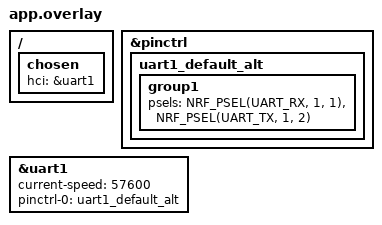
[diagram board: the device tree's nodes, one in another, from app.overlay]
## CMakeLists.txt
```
# SPDX-License-Identifier: Apache-2.0

cmake_minimum_required(VERSION 3.20.0)
find_package(Zephyr REQUIRED HINTS $ENV{ZEPHYR_BASE})
project(a2)
zephyr_library_include_directories(${ZEPHYR_BASE}/samples/bluetooth)

FILE(GLOB app_sources src/*.c)
target_sources(app PRIVATE ${app_sources})
```

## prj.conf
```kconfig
# Increased stack due to settings API usage
CONFIG_SYSTEM_WORKQUEUE_STACK_SIZE=2048

CONFIG_TEST=y
CONFIG_TEST_LOGGING_DEFAULTS=n
CONFIG_BT=y
CONFIG_LOG=y
CONFIG_BT_CENTRAL=y
CONFIG_BT_PERIPHERAL=y
CONFIG_BT_PRIVACY=y
CONFIG_BT_SMP=y
CONFIG_BT_PASSKEY_KEYPRESS=y
CONFIG_BT_SIGNING=y
CONFIG_BT_FIXED_PASSKEY=y
CONFIG_BT_ATT_PREPARE_COUNT=2
CONFIG_BT_GATT_CLIENT=y
CONFIG_BT_L2CAP_DYNAMIC_CHANNEL=y
CONFIG_BT_TINYCRYPT_ECC=y
CONFIG_BT_SHELL=y
CONFIG_BT_DEVICE_NAME="test shell"
CONFIG_BT_DEVICE_NAME_DYNAMIC=y
CONFIG_BT_L2CAP_TX_BUF_COUNT=4
CONFIG_BT_ID_MAX=2
CONFIG_BT_EATT=y
CONFIG_BT_L2CAP_ECRED=y
CONFIG_BT_GATT_DYNAMIC_DB=y
CONFIG_BT_GATT_NOTIFY_MULTIPLE=y
CONFIG_BT_HRS=y
CONFIG_BT_FILTER_ACCEPT_LIST=y
CONFIG_BT_REMOTE_INFO=y
CONFIG_BT_REMOTE_VERSION=y
CONFIG_BT_GATT_AUTO_DISCOVER_CCC=y

CONFIG_BT_SETTINGS=y
CONFIG_FLASH=y
CONFIG_FLASH_PAGE_LAYOUT=y
CONFIG_FLASH_MAP=y
CONFIG_NVS=y
CONFIG_SETTINGS=y

CONFIG_BT_EXT_ADV=y
CONFIG_BT_EXT_ADV_LEGACY_SUPPORT=y
CONFIG_BT_PER_ADV=y
CONFIG_BT_PER_ADV_SYNC=y

CONFIG_BT_USER_DATA_LEN_UPDATE=y
CONFIG_BT_AUTO_DATA_LEN_UPDATE=y

CONFIG_BT_USER_PHY_UPDATE=y
CONFIG_BT_AUTO_PHY_UPDATE=y

CONFIG_BT_ISO_BROADCASTER=y
CONFIG_BT_ISO_SYNC_RECEIVER=y
CONFIG_BT_ISO_CENTRAL=y
CONFIG_BT_ISO_PERIPHERAL=y

# Usage:
# `kernel log-level modulename severity`
# e.g.,
#
# kernel log-level bt_hci_core 0
# kernel log-level bt_l2cap 2
# kernel log-level bt_att 4
CONFIG_LOG_RUNTIME_FILTERING=y

# Errno message table. Disable to save ROM.
CONFIG_MINIMAL_LIBC_STRING_ERROR_TABLE=y


# shell
CONFIG_PRINTK=y
CONFIG_SHELL=y
CONFIG_LOG=y
CONFIG_LOG_CMDS=y
CONFIG_DATE_SHELL=y
```

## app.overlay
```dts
/ {
    chosen {
        hci = &uart1;
    };
};

&pinctrl {
    uart1_default_alt: uart1_default_alt {
        group1 {
            psels = <NRF_PSEL(UART_RX, 1, 1)>,
                    <NRF_PSEL(UART_TX, 1, 2)>;
        };
    };
 };
 
&uart1 {
    current-speed = <57600>;
    pinctrl-0 = <&uart1_default_alt>;
    status = "okay";
};
```

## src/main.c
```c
/** @file
 *  @brief Interactive Bluetooth LE shell application
 *
 *  Application allows implement Bluetooth LE functional commands performing
 *  simple diagnostic interaction between LE host stack and LE controller
 */

/*
 * Copyright (c) 2017 Nordic Semiconductor ASA
 * Copyright (c) 2015-2016 Intel Corporation
 *
 * SPDX-License-Identifier: Apache-2.0
 */

#include <errno.h>
#include <zephyr/types.h>
#include <stddef.h>
#include <stdlib.h>
#include <string.h>
#include <zephyr/sys/printk.h>
#include <zephyr/sys/byteorder.h>
#include <zephyr/kernel.h>
#include <zephyr/usb/usb_device.h>
#include <zephyr/drivers/uart.h>

#include <zephyr/shell/shell.h>

#include <zephyr/bluetooth/hci.h>
#include <zephyr/bluetooth/bluetooth.h>
#include <zephyr/bluetooth/uuid.h>
#include <zephyr/bluetooth/services/hrs.h>

#include <zephyr/logging/log.h>
#include <zephyr/shell/shell_uart.h>

#define DEVICE_NAME CONFIG_BT_DEVICE_NAME
#define STACKSIZE 1024 * 4
LOG_MODULE_REGISTER(main);

#if defined(CONFIG_BT_HRS)
static bool hrs_simulate;

static const struct bt_data ad[] = {
	BT_DATA_BYTES(BT_DATA_FLAGS, (BT_LE_AD_GENERAL | BT_LE_AD_NO_BREDR)),
	BT_DATA_BYTES(BT_DATA_UUID16_ALL,
		      BT_UUID_16_ENCODE(BT_UUID_HRS_VAL),
		      BT_UUID_16_ENCODE(BT_UUID_BAS_VAL),
		      BT_UUID_16_ENCODE(BT_UUID_DIS_VAL)),
};

static int cmd_hrs_simulate(const struct shell *sh,
			    size_t argc, char *argv[])
{
	static bool hrs_registered;
	int err;

	if (!strcmp(argv[1], "on")) {
		if (!hrs_registered && IS_ENABLED(CONFIG_BT_BROADCASTER)) {
			shell_print(sh, "Registering HRS Service");
			hrs_registered = true;
			err = bt_le_adv_start(BT_LE_ADV_CONN_NAME, ad,
					      ARRAY_SIZE(ad), NULL, 0);
			if (err) {
				shell_error(sh, "Advertising failed to start"
					    " (err %d)\n", err);
				return -ENOEXEC;
			}

			printk("Advertising successfully started\n");
		}

		shell_print(sh, "Start HRS simulation");
		hrs_simulate = true;
	} else if (!strcmp(argv[1], "off")) {
		shell_print(sh, "Stop HRS simulation");

		if (hrs_registered && IS_ENABLED(CONFIG_BT_BROADCASTER)) {
			bt_le_adv_stop();
		}

		hrs_simulate = false;
	} else {
		shell_print(sh, "Incorrect value: %s", argv[1]);
		shell_help(sh);
		return -ENOEXEC;
	}

	return 0;
}
#endif /* CONFIG_BT_HRS */

#define HELP_NONE "[none]"
#define HELP_ADDR_LE "<address: XX:XX:XX:XX:XX:XX> <type: (public|random)>"

SHELL_STATIC_SUBCMD_SET_CREATE(hrs_cmds,
#if defined(CONFIG_BT_HRS)
	SHELL_CMD_ARG(simulate, NULL,
		"register and simulate Heart Rate Service <value: on, off>",
		cmd_hrs_simulate, 2, 0),
#endif /* CONFIG_BT_HRS*/
	SHELL_SUBCMD_SET_END
);

static int cmd_hrs(const struct shell *sh, size_t argc, char **argv)
{
	shell_error(sh, "%s unknown parameter: %s", argv[0], argv[1]);

	return -ENOEXEC;
}

SHELL_CMD_ARG_REGISTER(hrs, &hrs_cmds, "Heart Rate Service shell commands",
		       cmd_hrs, 2, 0);

#if defined(CONFIG_BT_HRS)
static void hrs_notify(void)
{
	static uint8_t heartrate = 90U;

	/* Heartrate measurements simulation */
	heartrate++;
	if (heartrate == 160U) {
		heartrate = 90U;
	}

	bt_hrs_notify(heartrate);
}
#endif /* CONFIG_BT_HRS */

int main(void)
{
#if DT_NODE_HAS_COMPAT(DT_CHOSEN(zephyr_shell_uart), zephyr_cdc_acm_uart)
	const struct device *dev;
	uint32_t dtr = 0;

	dev = DEVICE_DT_GET(DT_CHOSEN(zephyr_shell_uart));
	if (!device_is_ready(dev) || usb_enable(NULL)) {
		return 0;
	}

	while (!dtr) {
		uart_line_ctrl_get(dev, UART_LINE_CTRL_DTR, &dtr);
		k_sleep(K_MSEC(100));
	}
#endif
	k_sleep(K_SECONDS(1));
	LOG_INF("Type \"help\" for supported commands.");
	LOG_INF("Before any Bluetooth commands you must `bt init` to initialize"
	       " the stack.");

	const struct shell *sh = shell_backend_uart_get_ptr();
    shell_execute_cmd(sh, "bt init");

	while (1) {
		k_sleep(K_SECONDS(1));

#if defined(CONFIG_BT_HRS)
		/* Heartrate measurements simulation */
		if (hrs_simulate) {
			hrs_notify();
		}
#endif /* CONFIG_BT_HRS */
	}
}


unsigned char hex_array[256];
static bool hex_set;

static int wifi(const struct shell *sh, size_t argc, char **argv)
{

	shell_error(sh, "%s unknown parameter: %s", argv[0], argv[1]);
	hex_set = true;
    char *input = argv[1];
    int len = strlen(input);
    int hex_len = len * 2; // Each character becomes two hex digits

    // Check if the hexadecimal array will exceed the maximum length
    if (hex_len >= 256) {
        printf("Input string is too long\n");
        return 1;
    }

    // Convert each character to its hexadecimal representation
    for (int i = 0; i < len; i++) {
        sprintf((char *)&hex_array[i * 2], "%02X", input[i]);
    }
	hex_array[hex_len] = '\0'; // Null terminator

   // Print the hexadecimal array
    printf("Hexadecimal array: %s\n", hex_array);

    return 0;
}

SHELL_CMD_REGISTER(wifi, NULL, "Connect WiFi", wifi);

void wifi_enable(void)
{
	const struct shell *sh = shell_backend_uart_get_ptr();

	k_sleep(K_SECONDS(2));
    LOG_INF("Starting wifi_enable thread");
	while (1) {
		k_sleep(K_SECONDS(1));
		if (hex_set) {
			char shell_command[300]; // Adjust size as needed
    		shell_execute_cmd(sh, "bt adv-create conn-scan identity");
		    int len = strlen(hex_array);

    		sprintf(shell_command, "bt adv-data %x09%s", len/2 +1, hex_array);
    		shell_execute_cmd(sh, shell_command);
    		shell_execute_cmd(sh, "bt adv-start");
			hex_set = false;
		}
	}

}

K_THREAD_DEFINE(wifi_enable_id, STACKSIZE, wifi_enable, NULL, NULL, NULL, 0, 0, 0);
```

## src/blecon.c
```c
#include "blecon.h"

LOG_MODULE_REGISTER(blecon);

int blue_blecon_init(void)
{
	LOG_INF("Starting blue_blecon_init");
	LOG_INF("Exiting %s.", __func__);
	return 0;
}

bt_addr_le_t global_rece_addr;
static int blecon(const struct shell *sh, size_t argc, char **argv)
{
	struct getopt_state *state;
	char *svalue = NULL;
	int c;

	while ((c = getopt(argc, argv, "hps:")) != -1)
	{
		state = getopt_state_get();
		switch (c)
		{
		case 'p':
			blecon_receive_stop();
			break;
		case 's':
			char type[2] = "";
			svalue = state->optarg;
			sprintf(type, "%d", BT_ADDR_LE_RANDOM);
			bt_addr_le_from_str(svalue, type, &global_rece_addr);
			blecon_observer_start();
			break;
		case 'h':
			/* When getopt is active shell is not parsing
			 * command handler to print help message. It must
			 * be done explicitly.
			 */
			shell_help(sh);
			return SHELL_CMD_HELP_PRINTED;
		case '?':
			if (state->optopt == 's')
			{
				shell_print(sh,
							"Option -%c requires an argument.",
							state->optopt);
			}
			else if (isprint(state->optopt) != 0)
			{
				shell_print(sh,
							"Unknown option `-%c'.",
							state->optopt);
			}
			else
			{
				shell_print(sh,
							"Unknown option character `\\x%x'.",
							state->optopt);
			}
			return 1;
		default:
			break;
		}
	}

	return 0;
}

SHELL_CMD_REGISTER(blecon, NULL, "BLE Receive ibeacon", blecon);
```

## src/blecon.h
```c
#include <stdlib.h>
#include <string.h>
#include <stdio.h>
#include <unistd.h>
#include <ctype.h>
#include <zephyr/device.h>
#include <zephyr/sys/util.h>
#include <zephyr/drivers/sensor.h>
#include <zephyr/kernel.h>
#include <zephyr/logging/log.h>
#include <zephyr/shell/shell.h>
#include <zephyr/bluetooth/bluetooth.h>
#include <zephyr/bluetooth/uuid.h>
#include <zephyr/bluetooth/addr.h>

int blue_blecon_init(void);
int blecon_observer_start(void);
int blecon_receive_stop(void);

extern bt_addr_le_t global_rece_addr;
```

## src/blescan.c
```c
#include "blescan.h"

LOG_MODULE_REGISTER(blescan);

int blue_blescan_init(void)
{
	int err;

	LOG_INF("Starting blue_blescan_init\n");

	/* Initialize the Bluetooth Subsystem */
	err = bt_enable(NULL);
	if (err)
	{
		LOG_ERR("Bluetooth init failed (err %d)\n", err);
		return 0;
	}

	LOG_INF("Exiting %s.\n", __func__);
	return 0;
}

bt_addr_le_t global_filt_addr;
bool global_filt_enable;
static int blescan(const struct shell *sh, size_t argc, char **argv)
{
	struct getopt_state *state;
	char *cvalue = NULL, *fvalue = NULL;
	int sflag = 0;
	int pflag = 0;
	int c;

	global_filt_enable = false;
	while ((c = getopt(argc, argv, "hspc:f:")) != -1)
	{
		state = getopt_state_get();
		switch (c)
		{
		case 's':
			sflag = 1;
			observer_start();
			break;
		case 'p':
			pflag = 1;
			observer_stop();
			break;
		case 'c':
			cvalue = state->optarg;
			break;
		case 'f':
			char type[2] = "";
			sprintf(type, "%d", BT_ADDR_LE_RANDOM);
			shell_print(sh, "%s", type);
			fvalue = state->optarg;
			bt_addr_le_from_str(fvalue, type, &global_filt_addr);
			global_filt_enable = true;
			break;
		case 'h':
			/* When getopt is active shell is not parsing
			 * command handler to print help message. It must
			 * be done explicitly.
			 */
			shell_help(sh);
			return SHELL_CMD_HELP_PRINTED;
		case '?':
			if (state->optopt == 'c')
			{
				shell_print(sh,
							"Option -%c requires an argument.",
							state->optopt);
			}
			else if (state->optopt == 'f')
			{
				shell_print(sh,
							"Option -%c requires an argument.",
							state->optopt);
			}
			else if (isprint(state->optopt) != 0)
			{
				shell_print(sh,
							"Unknown option `-%c'.",
							state->optopt);
			}
			else
			{
				shell_print(sh,
							"Unknown option character `\\x%x'.",
							state->optopt);
			}
			return 1;
		default:
			break;
		}
	}

	shell_print(sh, "sflag = %d, pflag = %d fvalue = %s", sflag, pflag, fvalue);
	return 0;
}

SHELL_CMD_REGISTER(blescan, NULL, "scan for other BLE devices", blescan);
```

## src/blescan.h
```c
#include <stdlib.h>
#include <string.h>
#include <stdio.h>
#include <unistd.h>
#include <ctype.h>
#include <zephyr/device.h>
#include <zephyr/kernel.h>
#include <zephyr/logging/log.h>
#include <zephyr/shell/shell.h>
#include <zephyr/bluetooth/bluetooth.h>
#include <zephyr/bluetooth/addr.h>

int blue_blescan_init(void);
int observer_start(void);
int observer_stop(void);

extern bt_addr_le_t global_filt_addr;
extern bool global_filt_enable;
```

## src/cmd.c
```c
#include <stdlib.h>
#include <string.h>
#include <zephyr/device.h>
#include <zephyr/drivers/uart.h>
#include <zephyr/kernel.h>
#include <zephyr/logging/log.h>
#include <zephyr/shell/shell.h>
#include <zephyr/shell/shell_uart.h>
LOG_MODULE_REGISTER(hci);
#define STACKSIZE 1024 * 4

static int gled(const struct shell *sh, size_t argc, char **argv)
{
	const struct shell *shv = shell_backend_uart_get_ptr();

	shell_error(sh, "%s unknown parameter: %s", argv[0], argv[1]);
	// printk("Type \"help\" for supported commands.");
    shell_execute_cmd(shv, "bt init");

    return 0;
}

SHELL_CMD_REGISTER(gled, NULL, "Control the GCU (c) User LEDs", gled);


// void print(void)
// {
//     LOG_INF("Starting print thread");
// }

// K_THREAD_DEFINE(print_id, STACKSIZE, print, NULL, NULL, NULL, K_IDLE_PRIO, 0, 0);
```

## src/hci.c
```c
#include "hci.h"

LOG_MODULE_REGISTER(hci);

#define UART_DEVICE_NODE DT_CHOSEN(hci)

/* Global varaibles */
static const struct device *const uart_dev = DEVICE_DT_GET(UART_DEVICE_NODE);

K_MSGQ_DEFINE(gcu_display_msgq, sizeof(struct gcu_display), 10, 1);

/* queue to store up to 10 messages (aligned to 4-byte boundary) */
K_MSGQ_DEFINE(uart_msgq, MSG_SIZE, 10, 4);

/* receive buffer used in UART ISR callback */
static char rx_buf[MSG_SIZE];
static int rx_buf_pos;
static bool preamble_received = false;
static uint8_t expected_length = 0;
static char g_gcu_type = GCUINTI;
static char g_gcu_dev;
/* Global varaibles  END */

/*
 * Read characters from UART until line end is detected. Afterwards push the
 * data to the message queue.
 */
void serial_cb(const struct device *dev, void *user_data)
{
    uint8_t c;

    if (!uart_irq_update(uart_dev))
    {
        return;
    }

    if (!uart_irq_rx_ready(uart_dev))
    {
        return;
    }

    /* read until FIFO empty */
    while (uart_fifo_read(uart_dev, &c, 1) == 1)
    {
        if (!preamble_received)
        {
            if (c == PREAMBLE || c == '\n')
            {
                preamble_received = true;
                rx_buf[rx_buf_pos++] = c;
            }
        }
        else
        {
            rx_buf[rx_buf_pos++] = c;
            if (rx_buf_pos == 2)
            {
                expected_length = rx_buf[1] & 0x0f;
            }
            if ((rx_buf_pos > 2) && (rx_buf_pos == expected_length + 2))
            {
                /* if queue is full, message is silently dropped */
                k_msgq_put(&uart_msgq, &rx_buf, K_NO_WAIT);
                rx_buf_pos = 0;
                preamble_received = false;
                expected_length = 0;
            }
        }
        if (rx_buf_pos >= sizeof(rx_buf))
        {
            rx_buf_pos = 0;
            preamble_received = false;
            expected_length = 0;
        }
    }
}

void print_uart(char *buf, char len)
{
    for (int i = 0; i < len; i++)
    {
        uart_poll_out(uart_dev, buf[i]);
    }
}

static void print_cmd_sent(const char *buf, char len)
{
    char tmp[PRINT_SIZE];
    int cx = 0;

    for (int i = 0; i < len; i++)
    {
        cx += snprintf(tmp + cx, PRINT_SIZE - cx, "%02X ", buf[i]);
    }
    LOG_INF("Sent: %s, len=%d", tmp, len);
    return;
}

static void shell_print_cmd_sent(const struct shell *sh, const char *buf, char len)
{
    char tmp[PRINT_SIZE];
    int cx = 0;

    for (int i = 0; i < len; i++)
    {
        cx += snprintf(tmp + cx, PRINT_SIZE - cx, "%02X ", buf[i]);
    }
    shell_print(sh, "Sent: %s, len=%d", tmp, len);
    return;
}

int blue_hci_init(void)
{
    int ret;
    if (!device_is_ready(uart_dev))
    {
        LOG_ERR("UART device not found!");
        return 0;
    }

    /* configure interrupt and callback to receive data */
    ret = uart_irq_callback_user_data_set(uart_dev, serial_cb, NULL);
    if (ret < 0)
    {
        if (ret == -ENOTSUP)
        {
            LOG_ERR("Interrupt-driven UART API support not enabled");
        }
        else if (ret == -ENOSYS)
        {
            LOG_ERR("UART device does not support interrupt-driven API");
        }
        else
        {
            LOG_ERR("Error setting UART callback: %d", ret);
        }
        return 0;
    }
    uart_irq_rx_enable(uart_dev);

    return 0;
}

static int gcugraph(const struct shell *sh, size_t argc, char **argv)
{
    ARG_UNUSED(argc);
    g_gcu_type = GCUGRAPH;
    g_gcu_dev = atoi(argv[1]);

    return 0;
}

static int gcumeter(const struct shell *sh, size_t argc, char **argv)
{
    ARG_UNUSED(argc);
    g_gcu_type = GCUMETER;
    g_gcu_dev = atoi(argv[1]);

    return 0;
}

static int gcunumeric(const struct shell *sh, size_t argc, char **argv)
{
    ARG_UNUSED(argc);
    g_gcu_type = GCUNUMERIC;
    g_gcu_dev = atoi(argv[1]);

    return 0;
}

static int gcurec(const struct shell *sh, size_t argc, char **argv)
{
    struct getopt_state *state;
    int c;
    ARG_UNUSED(argc);
    int index, len, sensor_device_id = 0;
    bool start = false;
    char tx_buf[MSG_SIZE];
    hci_header header = {
        .preamble = PREAMBLE, .type = REQUEST, .len = GCUREC_LEN};

    while ((c = getopt(argc, argv, "hps")) != -1)
    {
        state = getopt_state_get();
        switch (c)
        {
        case 'p':
            start = false;
            break;
        case 's':
            start = true;
            break;
        case 'h':
            /* When getopt is active shell is not parsing
             * command handler to print help message. It must
             * be done explicitly.
             */
            shell_help(sh);
            return SHELL_CMD_HELP_PRINTED;
        case '?':
            if (isprint(state->optopt) != 0)
            {
                shell_print(sh,
                            "Unknown option `-%c'.",
                            state->optopt);
            }
            else
            {
                shell_print(sh,
                            "Unknown option character `\\x%x'.",
                            state->optopt);
            }
            return 1;
        default:
            break;
        }
    }

    g_gcu_dev = atoi(argv[2]);
    sensor_device_id = atoi(argv[2]);
    memset(tx_buf, 0, MSG_SIZE);
    index = 0;
    tx_buf[index++] = header.preamble;
    tx_buf[index++] = header.type << 4 | header.len;
    tx_buf[index++] = DEV_SD;
    if (start == false)
    {
        index += FILENAME_LEN_MAX;
        tx_buf[index++] = sensor_device_id;
        tx_buf[index++] = GCUREC_STOP;
    }
    else
    {
        shell_print(sh, "%s", argv[3]);
        strncpy(&tx_buf[index], argv[3], FILENAME_LEN_MAX);
        index += FILENAME_LEN_MAX;
        tx_buf[index++] = sensor_device_id;
        tx_buf[index++] = GCUREC_START;
    }

    len = sizeof(hci_header) + header.len;
    shell_print_cmd_sent(sh, tx_buf, len);
    print_uart(tx_buf, len);
    return 0;
}

static int sendres(const struct shell *sh, size_t argc, char **argv)
{
    ARG_UNUSED(argc);
    char tx_buf[MSG_SIZE];
    int index, len;
    hci_header header = {
        .preamble = PREAMBLE, .type = RESPONSE, .len = RESPONSE_LEN};

    memset(tx_buf, 0, MSG_SIZE);
    index = 0;
    tx_buf[index++] = header.preamble;
    tx_buf[index++] = header.type << 4 | header.len;
    tx_buf[index++] = DEV_LJ;
    tx_buf[index++] = RES_SUCCESS;

    len = sizeof(hci_header) + header.len;
    shell_print_cmd_sent(sh, tx_buf, len);
    print_uart(tx_buf, len);

    memset(tx_buf, 0, MSG_SIZE);
    index = 0;
    tx_buf[index++] = header.preamble;
    tx_buf[index++] = header.type << 4 | header.len;
    tx_buf[index++] = DEV_LJ;
    tx_buf[index++] = RES_FAIL;

    len = sizeof(hci_header) + header.len;
    shell_print_cmd_sent(sh, tx_buf, len);
    print_uart(tx_buf, len);
    memset(tx_buf, 0, MSG_SIZE);
    index = 0;
    tx_buf[index++] = header.preamble;
    tx_buf[index++] = header.type << 4 | header.len;
    tx_buf[index++] = DEV_BUTTON;
    tx_buf[index++] = RES_SUCCESS;

    len = sizeof(hci_header) + header.len;
    shell_print_cmd_sent(sh, tx_buf, len);
    print_uart(tx_buf, len);
    memset(tx_buf, 0, MSG_SIZE);
    index = 0;
    tx_buf[index++] = header.preamble;
    tx_buf[index++] = header.type << 4 | header.len;
    tx_buf[index++] = DEV_BUTTON;
    tx_buf[index++] = RES_FAIL;

    len = sizeof(hci_header) + header.len;
    shell_print_cmd_sent(sh, tx_buf, len);
    print_uart(tx_buf, len);
    return 0;
}

void consumer_thread(void)
{
    struct gcu_display data;
    int index, len;
    char tx_buf[MSG_SIZE];
    hci_header header = {
        .preamble = PREAMBLE, .type = REQUEST, .len = GCUGRAPH_LEN};
    int device_id;
    float16_t value;

    while (1)
    {
        /* get a data item */
        k_msgq_get(&gcu_display_msgq, &data, K_FOREVER);

        /* process data item */
        LOG_DBG("%d %.1f", data.device_id, (double)data.value);

        device_id = data.device_id;
        value = data.value;
        if (g_gcu_type == GCUINTI)
        {
            LOG_DBG("g_gcu_type is GCUINTI");
            continue;
        }
        if (g_gcu_dev != device_id)
        {
            LOG_DBG("g_gcu_dev %d != device_id %d", g_gcu_dev, device_id);
            continue;
        }
        memset(tx_buf, 0, MSG_SIZE);
        index = 0;
        tx_buf[index++] = header.preamble;
        tx_buf[index++] = header.type << 4 | header.len;
        tx_buf[index++] = device_id;
        memcpy(&tx_buf[index], &value, sizeof(value));
        index += sizeof(value);
        tx_buf[index++] = g_gcu_type;

        len = sizeof(hci_header) + header.len;
        print_cmd_sent(tx_buf, len);
        print_uart(tx_buf, len);
        LOG_INF("%d %.1f", data.device_id, (double)data.value);
    }
}

void print(void)
{
    LOG_INF("Starting print thread");
    char tx_buf[MSG_SIZE];

    /* indefinitely wait for input from the user */
    while (k_msgq_get(&uart_msgq, &tx_buf, K_FOREVER) == 0)
    {
        char tmp[PRINT_SIZE];
        int cx = 0, length = 0;

        length = (tx_buf[LEN_BYTE] & LEN_BYTE_MASK) + 2;

        for (int i = 0; i < length && i < PRINT_SIZE; i++)
        {
            cx += snprintf(tmp + cx, sizeof(tmp) - cx, "%02X ", tx_buf[i]);
        }
        LOG_INF("Received: %s", tmp);

        if (tx_buf[2] == 0x2)
        {
            if (tx_buf[3] == 0x1)
            {
                LOG_INF("Button on ");
            }
            else
            {
                LOG_INF("Button off ");
            }
        }
        else /* (tx_buf[2] != 0x2) */
        {
            if (tx_buf[3] == 0x1)
            {
                LOG_INF("Response success ");
            }
            else
            {
                LOG_INF("Response fail ");
            }
        }
    }
    LOG_INF("Exiting %s thread.", __func__);
}

SHELL_CMD_REGISTER(sendres, NULL, "send response data to myself", sendres);
SHELL_CMD_REGISTER(gcugraph, NULL, "displays the selected sensor values as a graph plot", gcugraph);
SHELL_CMD_REGISTER(gcumeter, NULL, "displays the selected sensor values as a meter widget", gcumeter);
SHELL_CMD_REGISTER(gcunumeric, NULL, "displays the selected sensor values as a numeric value", gcunumeric);
SHELL_CMD_REGISTER(gcurec, NULL, "start/stop continuously recording the selected sensor", gcurec);

K_THREAD_DEFINE(print_id, STACKSIZE, print, NULL, NULL, NULL, K_IDLE_PRIO, 0, 0);
K_THREAD_DEFINE(consumer_thread_id, STACKSIZE, consumer_thread, NULL, NULL, NULL, K_IDLE_PRIO, 0, 0);
```

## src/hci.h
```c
#include <stdlib.h>
#include <string.h>
#include <unistd.h>
#include <ctype.h>
#include <zephyr/device.h>
#include <zephyr/drivers/uart.h>
#include <zephyr/kernel.h>
#include <zephyr/logging/log.h>
#include <zephyr/shell/shell.h>
#include <zephyr/dsp/types.h>

/* size of stack area used by each thread */
#define STACKSIZE 1024 * 4

/* scheduling priority used by each thread */
#define PRIORITY1 1
#define PRIORITY7 7

#define MSG_SIZE 32
#define PRINT_SIZE 64

/* byte 0 */
#define PREAMBLE 0xAA

/* byte 1, low 4 bit */
#define REQUEST 0x01
#define RESPONSE 0x02

/* byte 1, high 4 bit  */
#define LEN_BYTE 0x1
#define LEN_BYTE_MASK 0xF
#define GLED_LEN 0x2
#define GPB_LEN 0x2
#define POINT_LEN 0x6
#define DAC_LEN 0x6
#define LJ_LEN 0x5
#define CIRCLE_LEN 0x7
#define RESPONSE_LEN 0x2
#define GCUGRAPH_LEN 0x4
#define GCUREC_LEN 0xC

/* byte 2 */
#define DEV_LED 0x01
#define DEV_BUTTON 0x02
#define DEV_DAC 0x03
#define DEV_LJ 0x04
#define DEV_TEMP 0x05
#define DEV_HUM 0x06
#define DEV_PRE 0x07
#define DEV_TVOC 0x08
#define DEV_SD 0x13

#define RES_SUCCESS 0x01
#define RES_FAIL 0x02

/* gcu type */
#define GCUGRAPH 0x01
#define GCUMETER 0x02
#define GCUNUMERIC 0x03
#define GCUINTI 0xFF
#define GCUREC_START 0x01
#define GCUREC_STOP 0x02

#define FILENAME_LEN_MAX 0x09

typedef struct
{
    uint8_t preamble;
    uint8_t type : 4;
    uint8_t len : 4;
} hci_header;

struct gcu_display
{
    int device_id;
    float16_t value;
};
extern struct k_msgq gcu_display_msgq;

/* Function declaration */
void process_packet(const uint8_t *packet, size_t length);
int blue_hci_init(void);
/* Function declaration END */
```

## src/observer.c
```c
/*
 * Copyright (c) 2022 Nordic Semiconductor ASA
 * Copyright (c) 2015-2016 Intel Corporation
 *
 * SPDX-License-Identifier: Apache-2.0
 */

#include <zephyr/sys/printk.h>
#include <zephyr/bluetooth/bluetooth.h>
#include <zephyr/bluetooth/hci.h>
#include "blescan.h"
#include "blecon.h"
#include "hci.h"

#define NAME_LEN 30

LOG_MODULE_REGISTER(observer);

#define IDX_OFFSET 5
#define IDX_MajorL 20 + IDX_OFFSET
#define IDX_MajorH 21 + IDX_OFFSET
#define IDX_MinorL 22 + IDX_OFFSET
#define IDX_MinorH 23 + IDX_OFFSET

static void value_send(int device_id, float16_t value)
{
	struct gcu_display data;

	data.device_id = device_id;
	data.value = value;
	/* send data to consumers */
	while (k_msgq_put(&gcu_display_msgq, &data, K_NO_WAIT) != 0)
	{
		/* message queue is full: purge old data & try again */
		k_msgq_purge(&gcu_display_msgq);
	}
}

void blecon_device_found(const bt_addr_le_t *addr, int8_t rssi, uint8_t type,
						 struct net_buf_simple *ad)
{
	char addr_str[BT_ADDR_LE_STR_LEN];
	bt_addr_le_t *filt_addr = &global_rece_addr;

	bt_addr_le_to_str(addr, addr_str, sizeof(addr_str));
	if (!ad)
	{
		LOG_ERR("ad is null");
		return;
	}

	if (bt_addr_eq(&(filt_addr->a), &(addr->a)))
	{
		float16_t value = 0;
		LOG_DBG("Received: %s (RSSI %d), type %u, AD data len %u",
				addr_str, rssi, type, ad->len);
		if (ad->len < 30)
		{
			LOG_ERR("ad->len < 30");
			return;
		}
		memcpy(&value, &(ad->data[IDX_MinorL]), sizeof(float16_t));
		LOG_DBG("dev: %X value: %X %X %.1f", ad->data[IDX_MajorL],
				ad->data[IDX_MinorL], ad->data[IDX_MinorH], (double)value);
		value_send(ad->data[IDX_MajorL], value);
	}
}

int blecon_observer_start(void)
{
	struct bt_le_scan_param scan_param = {
		.type = BT_LE_SCAN_TYPE_PASSIVE,
		.options = BT_LE_SCAN_OPT_NONE,
		.interval = BT_GAP_SCAN_FAST_INTERVAL,
		.window = BT_GAP_SCAN_FAST_WINDOW,
	};
	int err;

	err = bt_le_scan_start(&scan_param, blecon_device_found);
	if (err)
	{
		LOG_ERR("Start scanning failed (err %d)", err);
		return err;
	}
	LOG_INF("Started scanning...");

	return 0;
}

int blecon_receive_stop(void)
{
	int err;

	err = bt_le_scan_stop();
	if (err)
	{
		LOG_ERR("Stoped scanning failed (err %d)", err);
		return err;
	}
	LOG_INF("Stoped scanning...");
	return 0;
}

static void device_found(const bt_addr_le_t *addr, int8_t rssi, uint8_t type,
						 struct net_buf_simple *ad)
{
	char addr_str[BT_ADDR_LE_STR_LEN];
	bt_addr_le_t *filt_addr = &global_filt_addr;

	bt_addr_le_to_str(addr, addr_str, sizeof(addr_str));
	if (global_filt_enable)
	{
		if (bt_addr_eq(&(filt_addr->a), &(addr->a)))
		{
			LOG_INF("Device found(filt): %s (RSSI %d), type %u, AD data len %u",
					addr_str, rssi, type, ad->len);
		}
	}
	else
	{
		LOG_INF("Device found: %s (RSSI %d), type %u, AD data len %u",
				addr_str, rssi, type, ad->len);
	}
}

#if defined(CONFIG_BT_EXT_ADV)
static bool data_cb(struct bt_data *data, void *user_data)
{
	char *name = user_data;
	uint8_t len;

	switch (data->type)
	{
	case BT_DATA_NAME_SHORTENED:
	case BT_DATA_NAME_COMPLETE:
		len = MIN(data->data_len, NAME_LEN - 1);
		(void)memcpy(name, data->data, len);
		name[len] = '\0';
		return false;
	default:
		return true;
	}
}

static const char *phy2str(uint8_t phy)
{
	switch (phy)
	{
	case BT_GAP_LE_PHY_NONE:
		return "No packets";
	case BT_GAP_LE_PHY_1M:
		return "LE 1M";
	case BT_GAP_LE_PHY_2M:
		return "LE 2M";
	case BT_GAP_LE_PHY_CODED:
		return "LE Coded";
	default:
		return "Unknown";
	}
}

static void scan_recv(const struct bt_le_scan_recv_info *info,
					  struct net_buf_simple *buf)
{
	char le_addr[BT_ADDR_LE_STR_LEN];
	char name[NAME_LEN];
	uint8_t data_status;
	uint16_t data_len;

	(void)memset(name, 0, sizeof(name));

	data_len = buf->len;
	bt_data_parse(buf, data_cb, name);

	data_status = BT_HCI_LE_ADV_EVT_TYPE_DATA_STATUS(info->adv_props);

	bt_addr_le_to_str(info->addr, le_addr, sizeof(le_addr));
	printk("[DEVICE]: %s, AD evt type %u, Tx Pwr: %i, RSSI %i "
		   "Data status: %u, AD data len: %u Name: %s "
		   "C:%u S:%u D:%u SR:%u E:%u Pri PHY: %s, Sec PHY: %s, "
		   "Interval: 0x%04x (%u ms), SID: %u\n",
		   le_addr, info->adv_type, info->tx_power, info->rssi,
		   data_status, data_len, name,
		   (info->adv_props & BT_GAP_ADV_PROP_CONNECTABLE) != 0,
		   (info->adv_props & BT_GAP_ADV_PROP_SCANNABLE) != 0,
		   (info->adv_props & BT_GAP_ADV_PROP_DIRECTED) != 0,
		   (info->adv_props & BT_GAP_ADV_PROP_SCAN_RESPONSE) != 0,
		   (info->adv_props & BT_GAP_ADV_PROP_EXT_ADV) != 0,
		   phy2str(info->primary_phy), phy2str(info->secondary_phy),
		   info->interval, info->interval * 5 / 4, info->sid);
}

static struct bt_le_scan_cb scan_callbacks = {
	.recv = scan_recv,
};
#endif /* CONFIG_BT_EXT_ADV */

int observer_start(void)
{
	struct bt_le_scan_param scan_param = {
		.type = BT_LE_SCAN_TYPE_PASSIVE,
		.options = BT_LE_SCAN_OPT_FILTER_DUPLICATE,
		.interval = BT_GAP_SCAN_FAST_INTERVAL,
		.window = BT_GAP_SCAN_FAST_WINDOW,
	};
	int err;

#if defined(CONFIG_BT_EXT_ADV)
	bt_le_scan_cb_register(&scan_callbacks);
	printk("Registered scan callbacks\n");
#endif /* CONFIG_BT_EXT_ADV */

	err = bt_le_scan_start(&scan_param, device_found);
	if (err)
	{
		LOG_ERR("Start scanning failed (err %d)", err);
		return err;
	}
	LOG_INF("Started scanning...");

	return 0;
}

int observer_stop(void)
{
	int err;

	err = bt_le_scan_stop();
	if (err)
	{
		LOG_ERR("Stoped scanning failed (err %d)", err);
		return err;
	}
	LOG_INF("Stoped scanning...");
	return 0;
}
```
